# D1H register map
Vendor: Allwinner; File version: 1.0
Registers are 32-bit, read-write, reset 0x0 unless marked. A register's access mark holds for its fields unless they carry their own. Offsets are from the block's base; [hi:lo] are bit positions; {n}, {i} and the like mark numbered series; 'fields as' and 'values as' point back to an identical list.

## PWM — Pulse Width Modulation
Base 0x02000C00
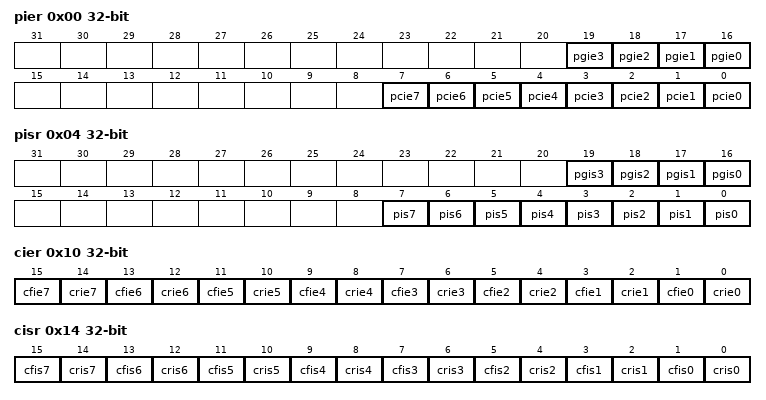
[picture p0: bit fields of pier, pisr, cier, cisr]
0x00 pier (reset mask 0xF00FF) — PWM IRQ Enable Register
  [n+16] pgie{n} (n=0..3) — PWM Group Interrupt Enable
    0=DISABLE; 1=ENABLE
  [n] pcie{n} (n=0..7) — PWM Channel Interrupt Enable
    0=DISABLE (PWM Channel Interrupt Disable); 1=ENABLE (PWM Channel Interrupt Enable)
0x04 pisr (reset mask 0xF00FF) — PWM IRQ Status Register
  [n+16] pgis{n} (n=0..3) write-1-clears — PWM Group Interrupt Status
  [n] pis{n} (n=0..7) write-1-clears — PWM Channel Interrupt Status . When the PWM channel counter reaches the Entire Cycle Value, this bit is set 1 by hardware. Writing 1 to clear this bit. . Reads 0: PWM channel 0 interrupt is not pending. . Reads 1: PWM channel 0 interrupt is pending. . Writes 0: No effect. . Writes 1: Clear PWM channel 0 interrupt status.
    0=NOT_PENDING; 1=PENDING
0x10 cier (reset mask 0xFFFF) — Capture IRQ Enable Register
  [2n+1] cfie{n} (n=0..7) — If the enable bit is set to 1, when the capture channel captures falling edge, it generates a capture channel pending.
    0=DISABLE (Capture channel fall lock interrupt disable); 1=ENABLE (Capture channel fall lock interrupt enable)
  [2n] crie{n} (n=0..7) — If the enable bit is set to 1, when the capture channel captures rising edge, it generates a capture channel pending.
    0=DISABLE (Capture channel rise lock interrupt disable); 1=ENABLE (Capture channel rise lock interrupt enable)
0x14 cisr (reset mask 0xFFFF) — Capture IRQ Status Register
  [2n+1] cfis{n} (n=0..7) write-1-clears — Status of the capture channel falling lock interrupt . When the capture channel captures falling edge, if the fall lock interrupt ( CFIE ) is enabled, this bit is set to 1 by hardware. Writing 1 to clear this bit. . Reads 0: The capture channel interrupt is not pending. . Reads 1: The capture channel interrupt is pending. . Writes 0: no effect. . Writes 1: Clear the status of the capture channel interrupt.
    0=NOT_PENDING; 1=PENDING
  [2n] cris{n} (n=0..7) write-1-clears — Status of the capture channel rising lock interrupt . When the capture channel captures rising edge, if the rise lock interrupt ( CRIE ) is enabled, this bit is set 1 by hardware. Writing 1 to clear this bit. . Reads 0: The capture channel interrupt is not pending. . Reads 1: The capture channel interrupt is pending. . Writes 0: no effect. . Writes 1: Clear the status of the capture channel interrupt.
    0=NOT_PENDING; 1=PENDING
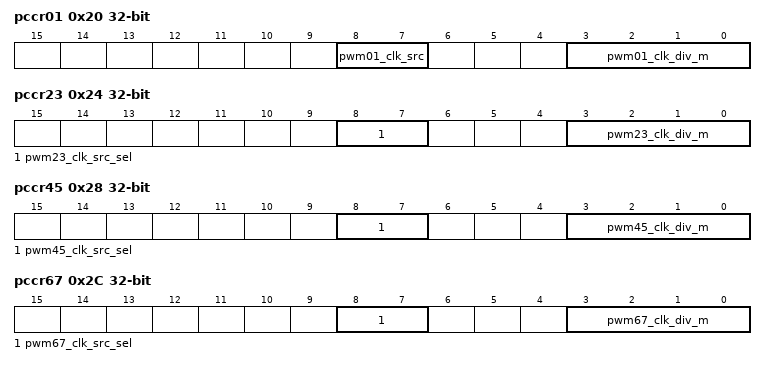
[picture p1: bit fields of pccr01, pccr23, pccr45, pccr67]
0x20 pccr01 — PWM01 Clock Configuration Register
  [8:7] pwm01_clk_src — Select PWM01 Clock Source
    0=HOSC; 1=APB0
  [3:0] pwm01_clk_div_m — PWM01 Clock Divide M
    0=M1 (/1); 1=M2 (/2); 2=M4 (/4); 3=M8 (/8); 4=M16 (/16); 5=M32 (/32); 6=M64 (/64); 7=M128 (/128); 8=M256 (/256)
0x24 pccr23 — PWM23 Clock Configuration Register
  [8:7] pwm23_clk_src_sel — Select PWM23 Clock Source
    0=HOSC; 1=APB0
  [3:0] pwm23_clk_div_m — PWM23 Clock Divide M
    values as pccr01.pwm01_clk_div_m
0x28 pccr45 — PWM45 Clock Configuration Register
  [8:7] pwm45_clk_src_sel — Select PWM45 Clock Source
    0=HOSC; 1=APB0
  [3:0] pwm45_clk_div_m — PWM45 Clock Divide M
    values as pccr01.pwm01_clk_div_m
0x2C pccr67 — PWM67 Clock Configuration Register
  [8:7] pwm67_clk_src_sel — Select PWM67 Clock Source
    0=HOSC; 1=APB0
  [3:0] pwm67_clk_div_m — PWM67 Clock Divide M
    values as pccr01.pwm01_clk_div_m
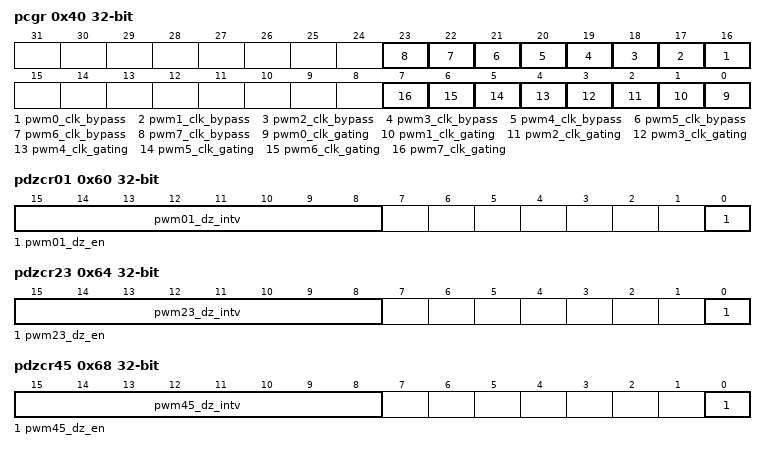
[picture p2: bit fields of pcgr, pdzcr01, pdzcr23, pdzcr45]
0x40 pcgr (reset mask 0xFF00FF) — PWM Clock Gating Register
  [n+16] pwm{n}_clk_bypass (n=0..7) — Bypass clock source (after pre-scale) to PWM output
    0=NOT_BYPASS; 1=BYPASS
  [n] pwm{n}_clk_gating (n=0..7) — Gating clock for PWM
    0=MASK; 1=PASS
0x60 pdzcr01 — PWM01 Dead Zone Control Register
  [15:8] pwm01_dz_intv — PWM01 Dead Zone Interval Value
  [0] pwm01_dz_en — PWM01 Dead Zone Enable
    0=DISABLE (Dead Zone disable); 1=ENABLE (Dead Zone enable)
0x64 pdzcr23 — PWM23 Dead Zone Control Register
  [15:8] pwm23_dz_intv — PWM23 Dead Zone Interval Value
  [0] pwm23_dz_en — PWM23 Dead Zone Enable
    0=DISABLE (Dead Zone disable); 1=ENABLE (Dead Zone enable)
0x68 pdzcr45 — PWM45 Dead Zone Control Register
  [15:8] pwm45_dz_intv — PWM45 Dead Zone Interval Value
  [0] pwm45_dz_en — PWM45 Dead Zone Enable
    0=DISABLE (Dead Zone disable); 1=ENABLE (Dead Zone enable)
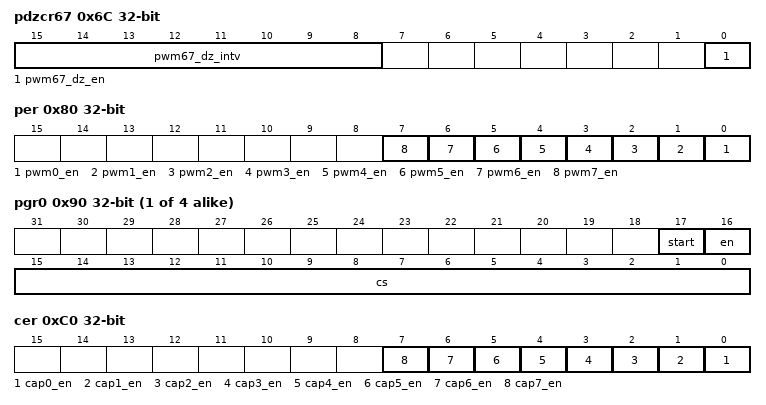
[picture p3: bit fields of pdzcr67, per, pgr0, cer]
0x6C pdzcr67 — PWM67 Dead Zone Control Register
  [15:8] pwm67_dz_intv — PWM67 Dead Zone Interval Value
  [0] pwm67_dz_en — PWM67 Dead Zone Enable
    0=DISABLE (Dead Zone disable); 1=ENABLE (Dead Zone enable)
0x80 per (reset mask 0xFF) — PWM Enable Register
  [n] pwm{n}_en (n=0..7) — When PWM is enabled, the 16-bit up-counter starts working and PWM channel is permitted to output PWM waveform.
    0=DISABLE (PWM disable); 1=ENABLE (PWM enable)
{0x90+4i} pgr{i} (i=0..3) — PWM Group[g] Register
  [17] start — The PWM channels selected in CS start to output PWM waveform at the same time.
  [16] en — PWM Group Enable.
  [15:0] cs — If bit[i] is set, the PWM i is selected as one channel of PWM Group[g].
0xC0 cer (reset mask 0xFF) — Capture Enable Register
  [n] cap{n}_en (n=0..7) — When enabling the capture function, the 16-bit up-counter starts working, and the capture channel is permitted to capture external falling edge or rising edge.
    0=DISABLE (Capture disable); 1=ENABLE (Capture enable)
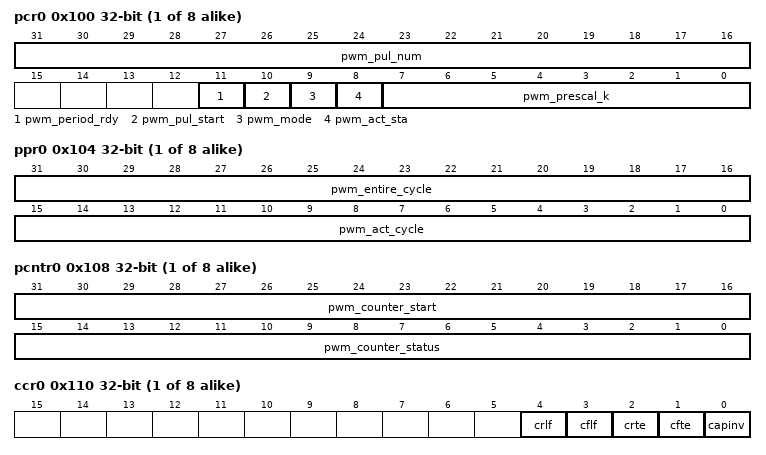
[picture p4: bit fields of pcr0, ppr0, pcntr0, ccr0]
{0x100+0x20*i} pcr{i} (i=0..7) — PWM Control Register
  [31:16] pwm_pul_num — In pulse mode, the PWM outputs pulse for PWM_CYCLE_NUM + 1 times and then stops
  [11] pwm_period_rdy ro — PWM Period Register Ready
    0=READY (PWM period register is ready to write); 1=BUSY (PWM period register is busy)
  [10] pwm_pul_start write-clears — PWM Pulse Output Start
    0=NO_EFFECT; 1=START (Output pulse for PWM_CYCLE_NM + 1)
  [9] pwm_mode — PWM Output Mode Select
    0=CYCLE (Cycle mode); 1=PULSE (Pulse mode)
  [8] pwm_act_sta — PWM Active State
    0=LOW (low level); 1=HIGH (high level)
  [7:0] pwm_prescal_k — PWM pre-scale K, actual pre-scale is (K + 1)
{0x104+0x20*i} ppr{i} (i=0..7) — PWM Period Register
  [31:16] pwm_entire_cycle — Number of the entire cycles in the PWM clock. . N: N + 1 cycles
  [15:0] pwm_act_cycle — Number of the active cycles in the PWM clock. . N: N cycles
{0x108+0x20*i} pcntr{i} (i=0..7) — PWM Count Register
  [31:16] pwm_counter_start — PWM counter value is set for phase control.
  [15:0] pwm_counter_status ro — On PWM output or capture input, reading this register could get the current value of the PWM 16-bit up-counter.
{0x10C+0x20*i} ppcntr{i} (i=0..7) ro — PWM Pulse Counter Register
  [15:0] pwm_pul_counter_status — On PWM output, reading this register could get the current value of the PWM pulse counter.
{0x110+0x20*i} ccr{i} (i=0..7) — Capture Control Register
  [4] crlf write-1-clears — When the capture channel captures a rising edge, the current value of the 16-bit up-counter is latched to CRLR, and then this bit is set 1 by hardware. . Write 1 to clear this bit.
  [3] cflf write-1-clears — When the capture channel captures a falling edge, the current value of the 16-bit up-counter is latched to CFLR, and then this bit is set 1 by hardware. . Write 1 to clear this bit.
  [2] crte — Rising edge capture trigger enable
  [1] cfte — Falling edge capture trigger enable
  [0] capinv — Inverse the signal input from capture channel before 16-bit counter of capture channel.
    0=NOT_INVERSE; 1=INVERSE
{0x114+0x20*i} crlr{i} (i=0..7) ro — Capture Rise Lock Register
  [15:0] crlr — When the capture channel captures a rising edge, the current value of the 16-bit up-counter is latched to the register.
{0x118+0x20*i} cflr{i} (i=0..7) ro — Capture Fall Lock Register
  [15:0] cflr — When the capture channel captures a falling edge, the current value of the 16-bit up-counter is latched to the register.
